# ATtiny167 register map
Vendor: Atmel; File version: 1.0
CPU: other r0p0, little endian, no MPU, no FPU, 4 interrupt priority bits
Registers are 8-bit, read-write, reset 0x0 unless marked. A register's access mark holds for its fields unless they carry their own. Offsets are from the block's base; [hi:lo] are bit positions.

## TC1 — Timer/Counter, 16-bit
Base 0x00800036
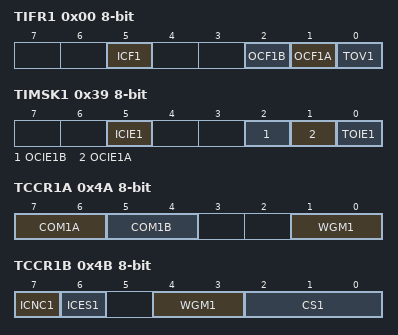
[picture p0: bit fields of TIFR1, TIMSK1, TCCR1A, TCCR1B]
0x00 TIFR1 — Timer/Counter1 Interrupt Flag register (read-only for debugger)
  [5] ICF1 — Timer/Counter1 Input Capture Flag
  [2] OCF1B — Timer/Counter1 Output Compare B Match Flag
  [1] OCF1A — Timer/Counter1 Output Compare A Match Flag
  [0] TOV1 — Timer/Counter1 Overflow Flag
0x39 TIMSK1 — Timer/Counter1 Interrupt Mask Register
  [5] ICIE1 — Timer/Counter1 Input Capture Interrupt Enable
  [2] OCIE1B — Timer/Counter1 Output Compare B Match Interrupt Enable
  [1] OCIE1A — Timer/Counter1 Output Compare A Match Interrupt Enable
  [0] TOIE1 — Timer/Counter1 Overflow Interrupt Enable
0x4A TCCR1A — Timer/Counter1 Control Register A
  [7:6] COM1A — Compare Output Mode 1A, bits
  [5:4] COM1B — Compare Output Mode 1B, bits
  [1:0] WGM1 — Pulse Width Modulator Select Bits
0x4B TCCR1B — Timer/Counter1 Control Register B
  [7] ICNC1 — Input Capture 1 Noise Canceler
  [6] ICES1 — Input Capture 1 Edge Select
  [4:3] WGM1 — Waveform Generation Mode Bits
  [2:0] CS1 — Timer/Counter1 Clock Select bits
    0=NO_CLOCK_SOURCE_STOPPED; 1=RUNNING_NO_PRESCALING; 2=RUNNING_CLK_8; 3=RUNNING_CLK_64; 4=RUNNING_CLK_256; 5=RUNNING_CLK_1024; 6=RUNNING_EXTCLK_TN_FALLING_EDGE; 7=RUNNING_EXTCLK_TN_RISING_EDGE
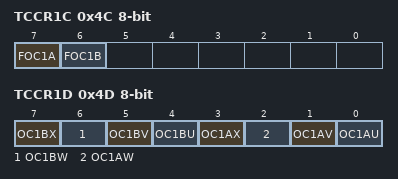
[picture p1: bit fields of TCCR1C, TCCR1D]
0x4C TCCR1C — Timer/Counter1 Control Register C
  [7] FOC1A — Timer/Counter1 Force Output Compare for Channel A
  [6] FOC1B — Timer/Counter1 Force Output Compare for Channel B
0x4D TCCR1D — Timer/Counter1 Control Register D
  [7] OC1BX — Timer/Counter1 Output Compare X-pin Enable for Channel B
  [6] OC1BW — Timer/Counter1 Output Compare W-pin Enable for Channel B
  [5] OC1BV — Timer/Counter1 Output Compare V-pin Enable for Channel B
  [4] OC1BU — Timer/Counter1 Output Compare U-pin Enable for Channel B
  [3] OC1AX — Timer/Counter1 Output Compare X-pin Enable for Channel A
  [2] OC1AW — Timer/Counter1 Output Compare W-pin Enable for Channel A
  [1] OC1AV — Timer/Counter1 Output Compare V-pin Enable for Channel A
  [0] OC1AU — Timer/Counter1 Output Compare U-pin Enable for Channel A
0x4E TCNT1 16-bit (reset mask 0xFF) — Timer/Counter1 Bytes
0x50 ICR1 16-bit (reset mask 0xFF) — Timer/Counter1 Input Capture Register Bytes
0x52 OCR1A 16-bit (reset mask 0xFF) — Timer/Counter1 Output Compare Register A Bytes
0x54 OCR1B 16-bit (reset mask 0xFF) — Timer/Counter1 Output Compare Register B Bytes

## USI — Universal Serial Interface
Base 0x008000B8
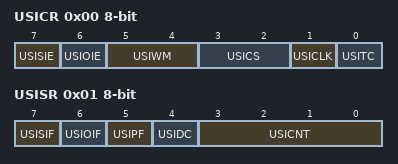
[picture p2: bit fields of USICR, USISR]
0x00 USICR — USI Control Register
  [7] USISIE — Start Condition Interrupt Enable
  [6] USIOIE — Counter Overflow Interrupt Enable
  [5:4] USIWM — USI Wire Mode Bits
    0=NORMAL_OPERATION; 1=THREE_WIRE_MODE; 2=TWO_WIRE_MODE; 3=TWO_WIRE_MODE_HELD_LOW
  [3:2] USICS — USI Clock Source Select Bits
  [1] USICLK — Clock Strobe
  [0] USITC — Toggle Clock Port Pin
0x01 USISR — USI Status Register (read-only for debugger)
  [7] USISIF — Start Condition Interrupt Flag
  [6] USIOIF — Counter Overflow Interrupt Flag
  [5] USIPF — Stop Condition Flag
  [4] USIDC — Data Output Collision
  [3:0] USICNT — USI Counter Value Bits
0x02 USIDR — USI Data Register
0x03 USIBR — USI Buffer Register (read-only for debugger)
0x04 USIPP — USI Pin Position

## WDT — Watchdog Timer
Base 0x00800060
0x00 WDTCR — Watchdog Timer Control Register (read-only for debugger)
  [7] WDIF — Watchdog Timeout Interrupt Flag
  [6] WDIE — Watchdog Timeout Interrupt Enable
  [4] WDCE — Watchdog Change Enable
  [3] WDE — Watch Dog Enable
  [5:0] WDP — Watchdog Timer Prescaler Bits
    0=OSCILLATOR_CYCLES_2K; 1=OSCILLATOR_CYCLES_4K; 2=OSCILLATOR_CYCLES_8K; 3=OSCILLATOR_CYCLES_16K; 4=OSCILLATOR_CYCLES_32K; 5=OSCILLATOR_CYCLES_64K; 6=OSCILLATOR_CYCLES_128K; 7=OSCILLATOR_CYCLES_256K
